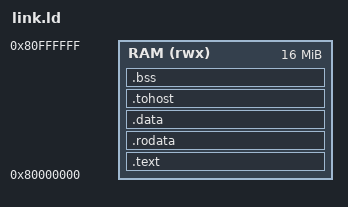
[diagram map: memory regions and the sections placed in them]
OUTPUT_ARCH("riscv")
ENTRY(_start)
MEMORY { RAM (rwx) : ORIGIN = 0x80000000, LENGTH = 16M }
SECTIONS
{
  .text   : { *(.text.init) *(.text .text.*) } > RAM
  .rodata : { *(.rodata .rodata.* .srodata .srodata.*) } > RAM
  .data   : { *(.data .data.* .sdata .sdata.*) } > RAM
  .tohost : { *(.tohost) } > RAM
  .bss    : { __bss_start = .; *(.bss .bss.* .sbss .sbss.* COMMON); . = ALIGN(4); __bss_end = .; } > RAM
  __stack_top = ORIGIN(RAM) + LENGTH(RAM);
}
